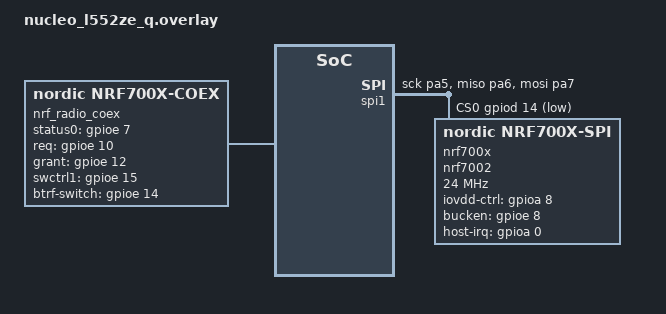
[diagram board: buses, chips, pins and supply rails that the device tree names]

&spi1{
    status = "okay";

    pinctrl-0 = <&spi1_sck_pa5 &spi1_miso_pa6 &spi1_mosi_pa7>;
    pinctrl-names = "default";
    cs-gpios = <&gpiod 14 GPIO_ACTIVE_LOW>;

    nrf700x: nrf7002@0 {
        compatible = "nordic,nrf700x-spi";
        status = "okay";
        reg = <0>;
        spi-max-frequency = <DT_FREQ_M(24)>;

        iovdd-ctrl-gpios = <&gpioa 8 GPIO_ACTIVE_HIGH>;
        bucken-gpios = <&gpioe 8 GPIO_ACTIVE_HIGH>;
        host-irq-gpios = <&gpioa 0 GPIO_ACTIVE_HIGH>;
    };
};

/ {
    chosen {
        zephyr,code-partition = &slot0_partition;
    };

    nrf_radio_coex: nrf7002-coex {
        status = "okay";
        compatible = "nordic,nrf700x-coex";
        status0-gpios = <&gpioe 7 GPIO_ACTIVE_HIGH>;
        req-gpios = <&gpioe 10 GPIO_ACTIVE_HIGH>;
        grant-gpios = <&gpioe 12 GPIO_ACTIVE_HIGH>;
        swctrl1-gpios = <&gpioe 15 GPIO_ACTIVE_HIGH>;
        btrf-switch-gpios = <&gpioe 14 GPIO_ACTIVE_HIGH>;
    };
};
